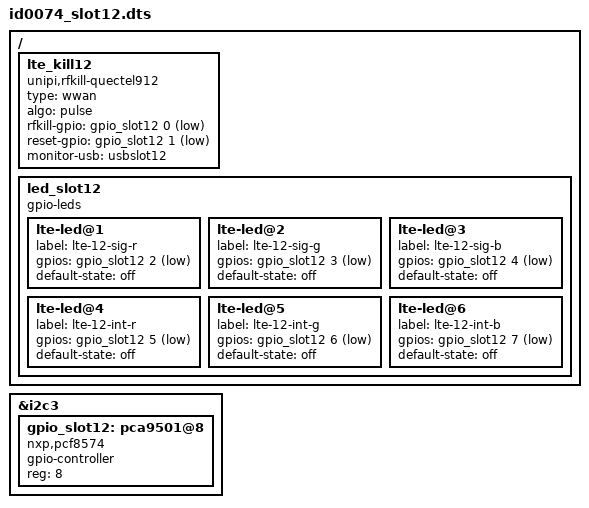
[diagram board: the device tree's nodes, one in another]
/dts-v1/;


/plugin/;

/ {
	fragment@1 {
		target = <&i2c3>;
		__overlay__ {
			#address-cells = <1>;
			#size-cells = <0>;
			gpio_slot12: pca9501@8 {
				compatible = "nxp,pcf8574";
				gpio-controller;
				#gpio-cells = <2>;
				reg = <8>;
				
			};
		};
	};

	fragment@4 {
		target-path = "/";
		__overlay__ {
			lte_kill12 {
				compatible = "unipi,rfkill-quectel912";
				type = "wwan";
				algo = "pulse";
				rfkill-gpio = <&gpio_slot12 0 1>;
				reset-gpio = <&gpio_slot12 1 1>;
				monitor-usb = "usbslot12";
			};
		};
	}; 

	fragment@5 {
		target-path = "/";
		__overlay__ {
			led_slot12 {
				compatible = "gpio-leds";
				lte-led@1 {
					label = "lte-12-sig-r";
					gpios = <&gpio_slot12 2 1>;
					default-state = "off";
				};
				lte-led@2 {
					label = "lte-12-sig-g";
					gpios = <&gpio_slot12 3 1>;
					default-state = "off";
				};
				lte-led@3 {
					label = "lte-12-sig-b";
					gpios = <&gpio_slot12 4 1>;
					default-state = "off";
				};
				lte-led@4 {
					label = "lte-12-int-r";
					gpios = <&gpio_slot12 5 1>;
					default-state = "off";
				};
				lte-led@5 {
					label = "lte-12-int-g";
					gpios = <&gpio_slot12 6 1>;
					default-state = "off";
				};
				lte-led@6 {
					label = "lte-12-int-b";
					gpios = <&gpio_slot12 7 1>;
					default-state = "off";
				};
			};
		};
	};
};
